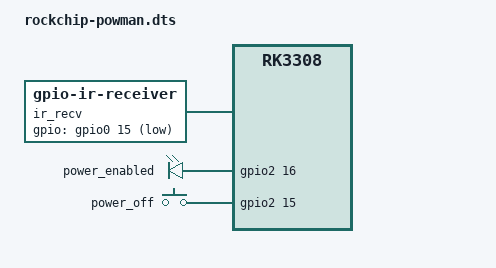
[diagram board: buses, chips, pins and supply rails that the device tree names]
/dts-v1/;
/plugin/;

/ {
    compatible = "radxa,rockpis", "rockchip,rk3308";

	fragment@0 {
		target-path = "/";
		__overlay__ {
            ir_recv: ir-receiver {
				status = "okay";
                compatible = "gpio-ir-receiver";
				// GPIO0_B7 GPIO_ACTIVE_LOW
                gpios = <&gpio0 15 1>;
            };
		};
	};

    fragment@2 {
        target-path = "/";
        __overlay__ {
			leds {
				pinctrl-0 = <&green_led &heartbeat_led &power_led_gpio>;
				power-en {
					linux,default-trigger = "default-on";
					function = "power";
					label = "power_enabled";
					default-state = "on";
					// GPIO2_C0
					gpios = <&gpio2 16 0>;
				};
			};
		
            gpio-keys-user {
                compatible = "gpio-keys";
                pinctrl-names = "default";
                pinctrl-0 = <&power_button_gpio>;

                power_button: power-button {
                    label = "power_off";
                    linux,input-type = <1>;
                    gpio-key,wakeup = <1>;
                    linux,code = <116>;
                    debounce-interval = <100>;
					// GPIO2_B7
                    gpios = <&gpio2 15 0>;
               };
           };
        };
    };

    fragment@3 {
        target = <&pinctrl>;
        __overlay__ {
            power_manager {
                power_button_gpio: power-button-gpio {
                    rockchip,pins = <2 15 0 &pcfg_pull_up>;
                };
                power_led_gpio: power-led-gpio {
                    rockchip,pins = <2 16 0 &pcfg_pull_none>;
                };
            };
        };
    };
};
